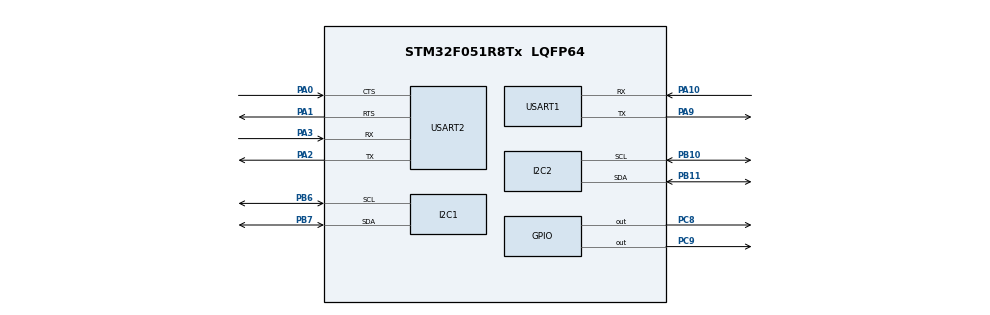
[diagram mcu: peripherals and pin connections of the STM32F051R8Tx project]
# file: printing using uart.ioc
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Mcu.Family=STM32F0
Mcu.Name=STM32F051R8Tx
Mcu.Package=LQFP64
PA0.Mode=CTS_RTS
PA0.Signal=USART2_CTS
PA1.Mode=CTS_RTS
PA1.Signal=USART2_RTS
PA10.Mode=Asynchronous
PA10.Signal=USART1_RX
PA2.Mode=Asynchronous
PA2.Signal=USART2_TX
PA3.Mode=Asynchronous
PA3.Signal=USART2_RX
PA9.Mode=Asynchronous
PA9.Signal=USART1_TX
PB10.Mode=I2C
PB10.Signal=I2C2_SCL
PB11.Mode=I2C
PB11.Signal=I2C2_SDA
PB6.Mode=I2C
PB6.Signal=I2C1_SCL
PB7.Mode=I2C
PB7.Signal=I2C1_SDA
PC8.Signal=GPIO_Output
PC9.Signal=GPIO_Output
ProjectManager.HeapSize=0x200
ProjectManager.StackSize=0x400
ProjectManager.TargetToolchain=STM32CubeIDE
USART1.VirtualMode-Asynchronous=VM_ASYNC
USART2.VirtualMode-Asynchronous=VM_ASYNC
board=custom

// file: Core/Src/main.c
/* USER CODE BEGIN Header */
/**
  ******************************************************************************
  * @file           : main.c
  * @brief          : Main program body
  ******************************************************************************
  * @attention
  *
  * <h2><center>&copy; Copyright (c) 2021 STMicroelectronics.
  * All rights reserved.</center></h2>
  *
  * This software component is licensed by ST under BSD 3-Clause license,
  * the "License"; You may not use this file except in compliance with the
  * License. You may obtain a copy of the License at:
  *                        opensource.org/licenses/BSD-3-Clause
  *
  ******************************************************************************
  */
/* USER CODE END Header */
#include "main.h"

I2C_HandleTypeDef hi2c1;
I2C_HandleTypeDef hi2c2;

UART_HandleTypeDef huart1;
UART_HandleTypeDef huart2;

void SystemClock_Config(void);
static void MX_GPIO_Init(void);
static void MX_USART2_UART_Init(void);
static void MX_USART1_UART_Init(void);
static void MX_I2C1_Init(void);
static void MX_I2C2_Init(void);

int main(void)
{

  /* MCU Configuration--------------------------------------------------------*/

  /* Reset of all peripherals, Initializes the Flash interface and the Systick. */
  HAL_Init();

  /* Configure the system clock */
  SystemClock_Config();

  /* Initialize all configured peripherals */
  MX_GPIO_Init();
  MX_USART2_UART_Init();
  MX_USART1_UART_Init();
  MX_I2C1_Init();
  MX_I2C2_Init();
  /* USER CODE BEGIN 2 */

  char txData[40] = "Hello from Mayand \r\n";

  /* USER CODE END 2 */

  /* Infinite loop */
  /* USER CODE BEGIN WHILE */
  while (1)
  {
	  HAL_UART_Transmit(&huart2, (uint8_t *)txData, strlen(txData), 1000);
	  HAL_Delay(1000);

	  //char rxData[40];
	  //uint8_t s;
	  //if(HAL_UART_Receive(&huart2, strlen(txData), strlen(rxData), 100)==HAL_OK)
	  //HAL_GPIO_TogglePin (GPIOC, GPIO_PIN_8);
	  //HAL_Delay (100);
    /* USER CODE END WHILE */

  }
}

void SystemClock_Config(void)
{
  RCC_OscInitTypeDef RCC_OscInitStruct = {0};
  RCC_ClkInitTypeDef RCC_ClkInitStruct = {0};
  RCC_PeriphCLKInitTypeDef PeriphClkInit = {0};

  /** Initializes the RCC Oscillators according to the specified parameters
  * in the RCC_OscInitTypeDef structure.
  */
  RCC_OscInitStruct.OscillatorType = RCC_OSCILLATORTYPE_HSI;
  RCC_OscInitStruct.HSIState = RCC_HSI_ON;
  RCC_OscInitStruct.HSICalibrationValue = RCC_HSICALIBRATION_DEFAULT;
  RCC_OscInitStruct.PLL.PLLState = RCC_PLL_NONE;
  if (HAL_RCC_OscConfig(&RCC_OscInitStruct) != HAL_OK)
  {
    Error_Handler();
  }
  /** Initializes the CPU, AHB and APB buses clocks
  */
  RCC_ClkInitStruct.ClockType = RCC_CLOCKTYPE_HCLK|RCC_CLOCKTYPE_SYSCLK
                              |RCC_CLOCKTYPE_PCLK1;
  RCC_ClkInitStruct.SYSCLKSource = RCC_SYSCLKSOURCE_HSI;
  RCC_ClkInitStruct.AHBCLKDivider = RCC_SYSCLK_DIV1;
  RCC_ClkInitStruct.APB1CLKDivider = RCC_HCLK_DIV1;

  if (HAL_RCC_ClockConfig(&RCC_ClkInitStruct, FLASH_LATENCY_0) != HAL_OK)
  {
    Error_Handler();
  }
  PeriphClkInit.PeriphClockSelection = RCC_PERIPHCLK_USART1|RCC_PERIPHCLK_I2C1;
  PeriphClkInit.Usart1ClockSelection = RCC_USART1CLKSOURCE_PCLK1;
  PeriphClkInit.I2c1ClockSelection = RCC_I2C1CLKSOURCE_HSI;
  if (HAL_RCCEx_PeriphCLKConfig(&PeriphClkInit) != HAL_OK)
  {
    Error_Handler();
  }
}

static void MX_I2C1_Init(void)
{

  hi2c1.Instance = I2C1;
  hi2c1.Init.Timing = 0x2000090E;
  hi2c1.Init.OwnAddress1 = 0;
  hi2c1.Init.AddressingMode = I2C_ADDRESSINGMODE_7BIT;
  hi2c1.Init.DualAddressMode = I2C_DUALADDRESS_DISABLE;
  hi2c1.Init.OwnAddress2 = 0;
  hi2c1.Init.OwnAddress2Masks = I2C_OA2_NOMASK;
  hi2c1.Init.GeneralCallMode = I2C_GENERALCALL_DISABLE;
  hi2c1.Init.NoStretchMode = I2C_NOSTRETCH_DISABLE;
  if (HAL_I2C_Init(&hi2c1) != HAL_OK)
  {
    Error_Handler();
  }
  /** Configure Analogue filter
  */
  if (HAL_I2CEx_ConfigAnalogFilter(&hi2c1, I2C_ANALOGFILTER_ENABLE) != HAL_OK)
  {
    Error_Handler();
  }
  /** Configure Digital filter
  */
  if (HAL_I2CEx_ConfigDigitalFilter(&hi2c1, 0) != HAL_OK)
  {
    Error_Handler();
  }

}

static void MX_I2C2_Init(void)
{

  hi2c2.Instance = I2C2;
  hi2c2.Init.Timing = 0x2000090E;
  hi2c2.Init.OwnAddress1 = 0;
  hi2c2.Init.AddressingMode = I2C_ADDRESSINGMODE_7BIT;
  hi2c2.Init.DualAddressMode = I2C_DUALADDRESS_DISABLE;
  hi2c2.Init.OwnAddress2 = 0;
  hi2c2.Init.OwnAddress2Masks = I2C_OA2_NOMASK;
  hi2c2.Init.GeneralCallMode = I2C_GENERALCALL_DISABLE;
  hi2c2.Init.NoStretchMode = I2C_NOSTRETCH_DISABLE;
  if (HAL_I2C_Init(&hi2c2) != HAL_OK)
  {
    Error_Handler();
  }
  /** Configure Analogue filter
  */
  if (HAL_I2CEx_ConfigAnalogFilter(&hi2c2, I2C_ANALOGFILTER_ENABLE) != HAL_OK)
  {
    Error_Handler();
  }
  /** Configure Digital filter
  */
  if (HAL_I2CEx_ConfigDigitalFilter(&hi2c2, 0) != HAL_OK)
  {
    Error_Handler();
  }

}

static void MX_USART1_UART_Init(void)
{

  huart1.Instance = USART1;
  huart1.Init.BaudRate = 38400;
  huart1.Init.WordLength = UART_WORDLENGTH_8B;
  huart1.Init.StopBits = UART_STOPBITS_1;
  huart1.Init.Parity = UART_PARITY_NONE;
  huart1.Init.Mode = UART_MODE_TX_RX;
  huart1.Init.HwFlowCtl = UART_HWCONTROL_NONE;
  huart1.Init.OverSampling = UART_OVERSAMPLING_16;
  huart1.Init.OneBitSampling = UART_ONE_BIT_SAMPLE_DISABLE;
  huart1.AdvancedInit.AdvFeatureInit = UART_ADVFEATURE_NO_INIT;
  if (HAL_UART_Init(&huart1) != HAL_OK)
  {
    Error_Handler();
  }

}

static void MX_USART2_UART_Init(void)
{

  huart2.Instance = USART2;
  huart2.Init.BaudRate = 38400;
  huart2.Init.WordLength = UART_WORDLENGTH_8B;
  huart2.Init.StopBits = UART_STOPBITS_1;
  huart2.Init.Parity = UART_PARITY_NONE;
  huart2.Init.Mode = UART_MODE_TX_RX;
  huart2.Init.HwFlowCtl = UART_HWCONTROL_NONE;
  huart2.Init.OverSampling = UART_OVERSAMPLING_16;
  huart2.Init.OneBitSampling = UART_ONE_BIT_SAMPLE_DISABLE;
  huart2.AdvancedInit.AdvFeatureInit = UART_ADVFEATURE_NO_INIT;
  if (HAL_UART_Init(&huart2) != HAL_OK)
  {
    Error_Handler();
  }

}

static void MX_GPIO_Init(void)
{
  GPIO_InitTypeDef GPIO_InitStruct = {0};

  /* GPIO Ports Clock Enable */
  __HAL_RCC_GPIOA_CLK_ENABLE();
  __HAL_RCC_GPIOB_CLK_ENABLE();
  __HAL_RCC_GPIOC_CLK_ENABLE();

  /*Configure GPIO pin Output Level */
  HAL_GPIO_WritePin(GPIOC, GPIO_PIN_8|GPIO_PIN_9, GPIO_PIN_RESET);

  /*Configure GPIO pins : PC8 PC9 */
  GPIO_InitStruct.Pin = GPIO_PIN_8|GPIO_PIN_9;
  GPIO_InitStruct.Mode = GPIO_MODE_OUTPUT_PP;
  GPIO_InitStruct.Pull = GPIO_NOPULL;
  GPIO_InitStruct.Speed = GPIO_SPEED_FREQ_LOW;
  HAL_GPIO_Init(GPIOC, &GPIO_InitStruct);

}

void Error_Handler(void)
{
}

/************************ (C) COPYRIGHT STMicroelectronics *****END OF FILE****/
